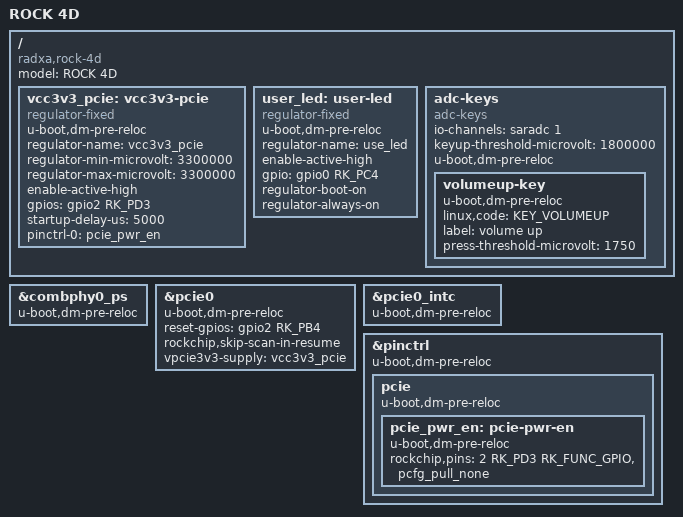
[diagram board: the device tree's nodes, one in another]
// SPDX-License-Identifier: (GPL-2.0+ OR MIT)
/*
 * Copyright (c) 2024 Rockchip Electronics Co., Ltd.
 * Copyright (c) 2024 Radxa Computer (Shenzhen) Co., Ltd.
 */

/dts-v1/;
#include "rk3576.dtsi"
#include "rk3576-u-boot.dtsi"
#include <dt-bindings/input/input.h>

/ {
	model = "ROCK 4D";
	compatible = "radxa,rock-4d", "rockchip,rk3576";

	vcc3v3_pcie: vcc3v3-pcie {
		u-boot,dm-pre-reloc;
		compatible = "regulator-fixed";
		regulator-name = "vcc3v3_pcie";
		regulator-min-microvolt = <3300000>;
		regulator-max-microvolt = <3300000>;
		enable-active-high;
		gpios = <&gpio2 RK_PD3 GPIO_ACTIVE_HIGH>;
		startup-delay-us = <5000>;
		pinctrl-names = "default";
		pinctrl-0 = <&pcie_pwr_en>;
	};

	user_led: user-led {
		u-boot,dm-pre-reloc;
		compatible = "regulator-fixed";
		regulator-name = "use_led";
		enable-active-high;
		gpio = <&gpio0 RK_PC4 GPIO_ACTIVE_HIGH>;
		regulator-boot-on;
		regulator-always-on;
	};

	adc-keys {
		compatible = "adc-keys";
		io-channels = <&saradc 1>;
		io-channel-names = "buttons";
		keyup-threshold-microvolt = <1800000>;
		u-boot,dm-pre-reloc;
		status = "okay";

		volumeup-key {
			u-boot,dm-pre-reloc;
			linux,code = <KEY_VOLUMEUP>;
			label = "volume up";
			press-threshold-microvolt = <1750>;
		};
	};
};

&combphy0_ps {
	u-boot,dm-pre-reloc;
	status = "okay";
};

&pcie0 {
	u-boot,dm-pre-reloc;
	reset-gpios = <&gpio2 RK_PB4 GPIO_ACTIVE_HIGH>;
	rockchip,skip-scan-in-resume;
	vpcie3v3-supply = <&vcc3v3_pcie>;
	status = "okay";
};

&pcie0_intc {
	u-boot,dm-pre-reloc;
};

&pinctrl {
	u-boot,dm-pre-reloc;
	pcie {
		u-boot,dm-pre-reloc;
		pcie_pwr_en: pcie-pwr-en {
			u-boot,dm-pre-reloc;
			rockchip,pins = <2 RK_PD3 RK_FUNC_GPIO &pcfg_pull_none>;
		};
	};
};
